# STM32L010RBT6 register map
File version: 1.0
Registers are 32-bit, access not given, reset 0x0 unless marked. A register's access mark holds for its fields unless they carry their own. Offsets are from the block's base; [hi:lo] are bit positions; {n}, {i} and the like mark numbered series; 'fields as' and 'values as' point back to an identical list.

## DMA1
Base 0x40020000
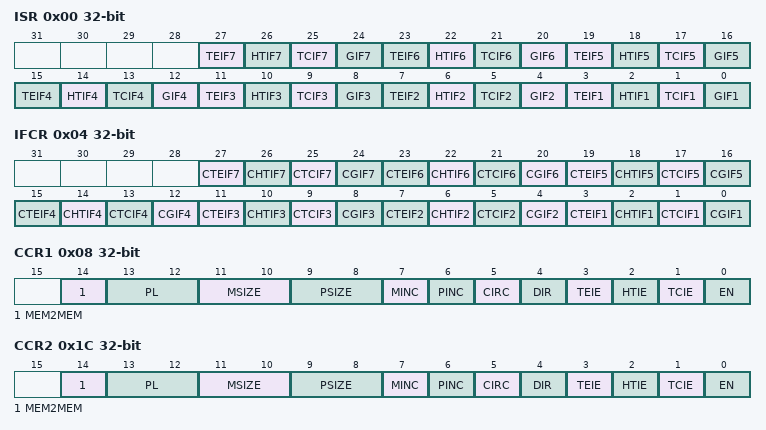
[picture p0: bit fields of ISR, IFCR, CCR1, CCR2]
0x00 ISR
  [4n-1] TEIF{n} (n=1..7), [4n-2] HTIF{n} (n=1..7), [4n-3] TCIF{n} (n=1..7), [4n-4] GIF{n} (n=1..7)
0x04 IFCR
  [4n-1] CTEIF{n} (n=1..7), [4n-2] CHTIF{n} (n=1..7), [4n-3] CTCIF{n} (n=1..7), [4n-4] CGIF{n} (n=1..7)
0x08 CCR1
  [14] MEM2MEM, [13:12] PL, [11:10] MSIZE, [9:8] PSIZE, [7] MINC, [6] PINC, [5] CIRC, [4] DIR, [3] TEIE, [2] HTIE, [1] TCIE, [0] EN
0x0C CNDTR1
  [15:0] NDT
0x10 CPAR1
  [31:0] PA
{0x0+0x14*i} CMAR{i} (i=1..7)
  [31:0] MA
0x1C CCR2
  fields as CCR1
0x20 CNDTR2
  [15:0] NDT
0x24 CPAR2
  [31:0] PA
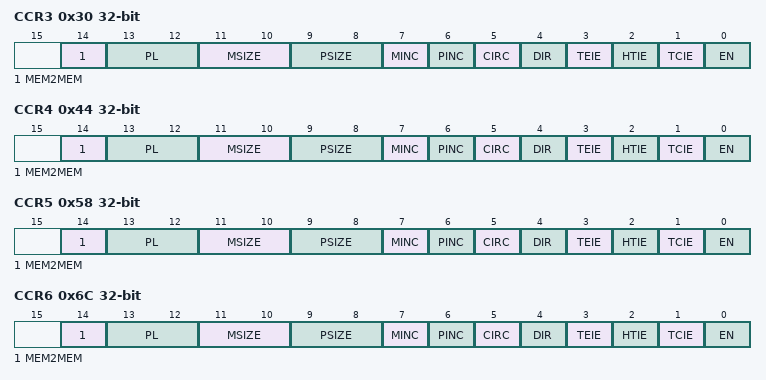
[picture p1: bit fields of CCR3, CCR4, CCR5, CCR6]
0x30 CCR3
  fields as CCR1
0x34 CNDTR3
  [15:0] NDT
0x38 CPAR3
  [31:0] PA
0x44 CCR4
  fields as CCR1
0x48 CNDTR4
  [15:0] NDT
0x4C CPAR4
  [31:0] PA
0x58 CCR5
  fields as CCR1
0x5C CNDTR5
  [15:0] NDT
0x60 CPAR5
  [31:0] PA
0x6C CCR6
  fields as CCR1
0x70 CNDTR6
  [15:0] NDT
0x74 CPAR6
  [31:0] PA
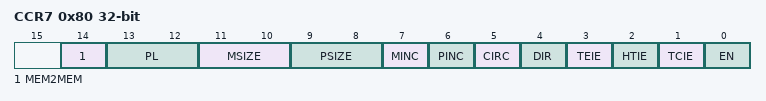
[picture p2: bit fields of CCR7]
0x80 CCR7
  fields as CCR1
0x84 CNDTR7
  [15:0] NDT
0x88 CPAR7
  [31:0] PA

## DMA1_CSELR
Base 0x400200A8
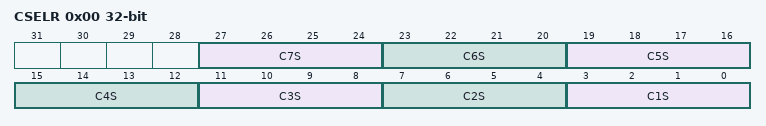
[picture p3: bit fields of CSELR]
0x00 CSELR
  [4n-1:4n-4] C{n}S (n=1..7)

## RCC
Base 0x40021000
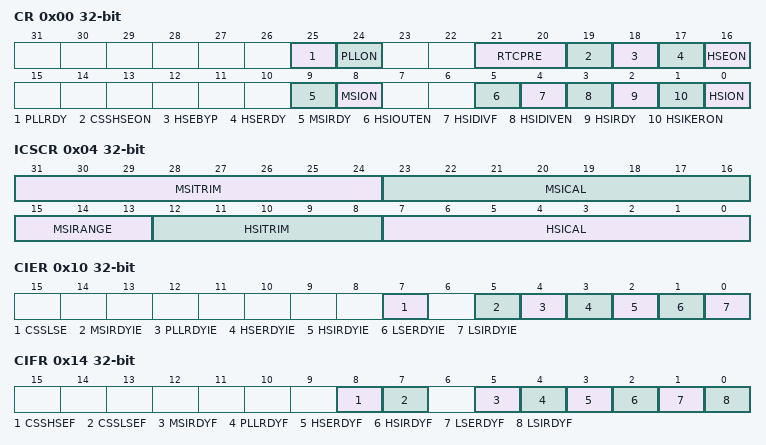
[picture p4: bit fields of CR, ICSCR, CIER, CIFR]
0x00 CR
  [25] PLLRDY, [24] PLLON, [21:20] RTCPRE, [19] CSSHSEON, [18] HSEBYP, [17] HSERDY, [16] HSEON, [9] MSIRDY, [8] MSION, [5] HSIOUTEN, [4] HSIDIVF, [3] HSIDIVEN, [2] HSIRDY, [1] HSIKERON, [0] HSION
0x04 ICSCR
  [31:24] MSITRIM, [23:16] MSICAL, [15:13] MSIRANGE, [12:8] HSITRIM, [7:0] HSICAL
0x08 CRRCR
0x0C CFGR
  [30:28] MCOPRE, [26] MCOSEL_HSE, [26:25] MCOSEL_LSI, [24] MCOSEL_SYSCLK, [23] PLLDIV3, [23:22] PLLDIV4, [21:18] PLLMUL, [16] PLLSRC, [15] STOPWUCK, [13:11] PPRE2, [10:8] PPRE1, [7:4] HPRE, [3:2] SWS, [1:0] SW
0x10 CIER
  [7] CSSLSE, [5] MSIRDYIE, [4] PLLRDYIE, [3] HSERDYIE, [2] HSIRDYIE, [1] LSERDYIE, [0] LSIRDYIE
0x14 CIFR
  [8] CSSHSEF, [7] CSSLSEF, [5] MSIRDYF, [4] PLLRDYF, [3] HSERDYF, [2] HSIRDYF, [1] LSERDYF, [0] LSIRDYF
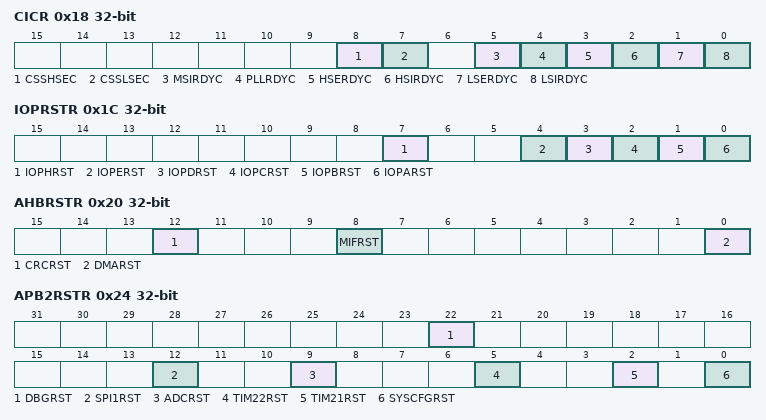
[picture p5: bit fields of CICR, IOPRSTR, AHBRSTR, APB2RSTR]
0x18 CICR
  [8] CSSHSEC, [7] CSSLSEC, [5] MSIRDYC, [4] PLLRDYC, [3] HSERDYC, [2] HSIRDYC, [1] LSERDYC, [0] LSIRDYC
0x1C IOPRSTR
  [7] IOPHRST, [4] IOPERST, [3] IOPDRST, [2] IOPCRST, [1] IOPBRST, [0] IOPARST
0x20 AHBRSTR
  [12] CRCRST, [8] MIFRST, [0] DMARST
0x24 APB2RSTR
  [22] DBGRST, [12] SPI1RST, [9] ADCRST, [5] TIM22RST, [2] TIM21RST, [0] SYSCFGRST
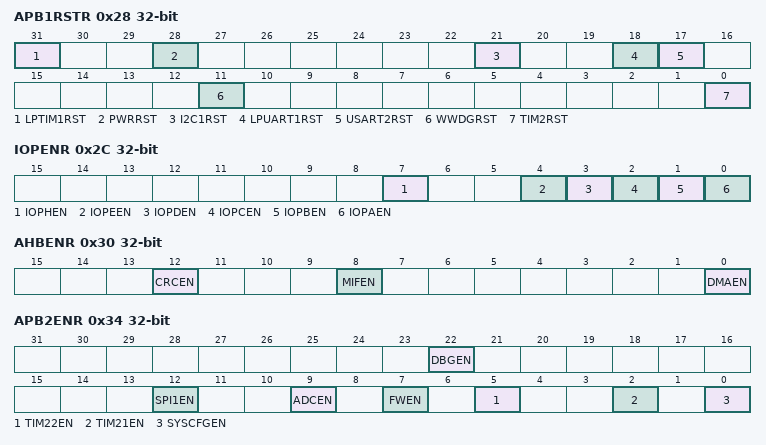
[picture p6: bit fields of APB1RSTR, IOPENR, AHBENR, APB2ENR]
0x28 APB1RSTR
  [31] LPTIM1RST, [28] PWRRST, [21] I2C1RST, [18] LPUART1RST, [17] USART2RST, [11] WWDGRST, [0] TIM2RST
0x2C IOPENR
  [7] IOPHEN, [4] IOPEEN, [3] IOPDEN, [2] IOPCEN, [1] IOPBEN, [0] IOPAEN
0x30 AHBENR
  [12] CRCEN, [8] MIFEN, [0] DMAEN
0x34 APB2ENR
  [22] DBGEN, [12] SPI1EN, [9] ADCEN, [7] FWEN, [5] TIM22EN, [2] TIM21EN, [0] SYSCFGEN
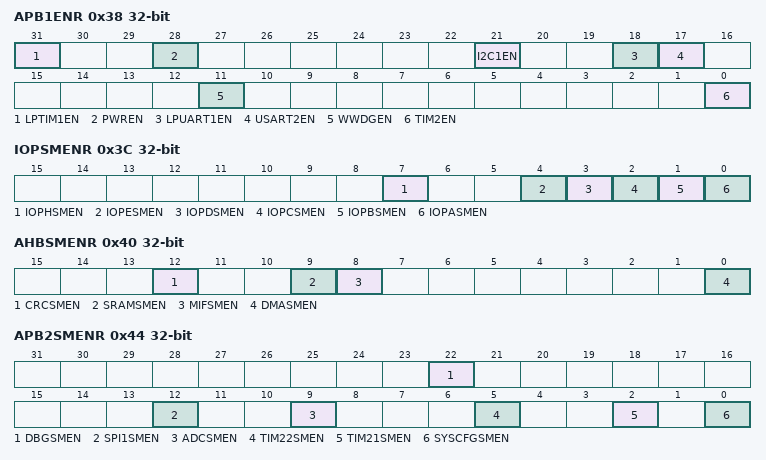
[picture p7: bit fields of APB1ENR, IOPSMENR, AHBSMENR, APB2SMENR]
0x38 APB1ENR
  [31] LPTIM1EN, [28] PWREN, [21] I2C1EN, [18] LPUART1EN, [17] USART2EN, [11] WWDGEN, [0] TIM2EN
0x3C IOPSMENR
  [7] IOPHSMEN, [4] IOPESMEN, [3] IOPDSMEN, [2] IOPCSMEN, [1] IOPBSMEN, [0] IOPASMEN
0x40 AHBSMENR
  [12] CRCSMEN, [9] SRAMSMEN, [8] MIFSMEN, [0] DMASMEN
0x44 APB2SMENR
  [22] DBGSMEN, [12] SPI1SMEN, [9] ADCSMEN, [5] TIM22SMEN, [2] TIM21SMEN, [0] SYSCFGSMEN
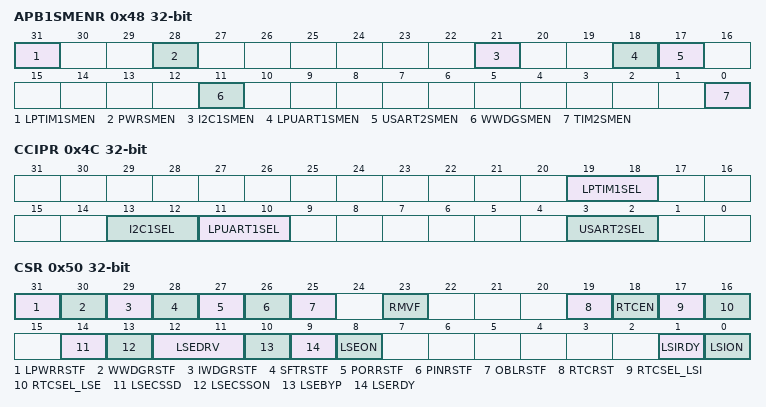
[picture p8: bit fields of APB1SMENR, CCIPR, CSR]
0x48 APB1SMENR
  [31] LPTIM1SMEN, [28] PWRSMEN, [21] I2C1SMEN, [18] LPUART1SMEN, [17] USART2SMEN, [11] WWDGSMEN, [0] TIM2SMEN
0x4C CCIPR
  [19:18] LPTIM1SEL, [13:12] I2C1SEL, [11:10] LPUART1SEL, [3:2] USART2SEL
0x50 CSR
  [31] LPWRRSTF, [30] WWDGRSTF, [29] IWDGRSTF, [28] SFTRSTF, [27] PORRSTF, [26] PINRSTF, [25] OBLRSTF, [23] RMVF, [19] RTCRST, [18] RTCEN, [17] RTCSEL_LSI, [16] RTCSEL_LSE, [14] LSECSSD, [13] LSECSSON, [12:11] LSEDRV, [10] LSEBYP, [9] LSERDY, [8] LSEON, [1] LSIRDY, [0] LSION

## FLASH
Base 0x40022000
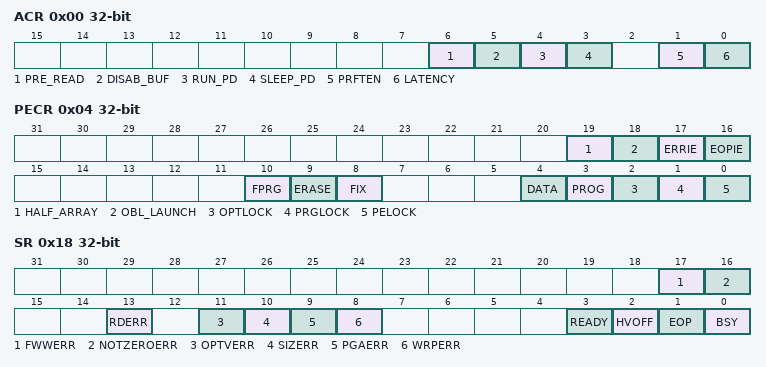
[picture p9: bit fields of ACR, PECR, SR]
0x00 ACR
  [6] PRE_READ, [5] DISAB_BUF, [4] RUN_PD, [3] SLEEP_PD, [1] PRFTEN, [0] LATENCY
0x04 PECR
  [19] HALF_ARRAY, [18] OBL_LAUNCH, [17] ERRIE, [16] EOPIE, [10] FPRG, [9] ERASE, [8] FIX, [4] DATA, [3] PROG, [2] OPTLOCK, [1] PRGLOCK, [0] PELOCK
0x08 PDKEYR
0x0C PEKEYR
0x10 PRGKEYR
0x14 OPTKEYR
0x18 SR
  [17] FWWERR, [16] NOTZEROERR, [13] RDERR, [11] OPTVERR, [10] SIZERR, [9] PGAERR, [8] WRPERR, [3] READY, [2] HVOFF, [1] EOP, [0] BSY
0x1C OPTR
  [31] BOOT1, [22] nRST_STDBY, [21] nRST_STOP, [22:20] USER, [19:16] BOR_LEV, [8] WPRMOD, [7:0] RDPROT
0x20 WRPR
  [15:0] WRP

## CRC
Base 0x40023000
0x00 DR
0x04 IDR 8-bit
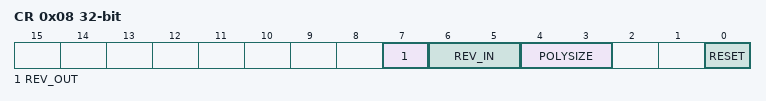
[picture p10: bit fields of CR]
0x08 CR
  [7] REV_OUT, [6:5] REV_IN, [4:3] POLYSIZE, [0] RESET
0x10 INIT
0x14 POL

## GPIOA
Base 0x50000000
Same registers: GPIOB 0x50000400, GPIOC 0x50000800, GPIOD 0x50000C00, GPIOE 0x50001000, GPIOH 0x50001C00
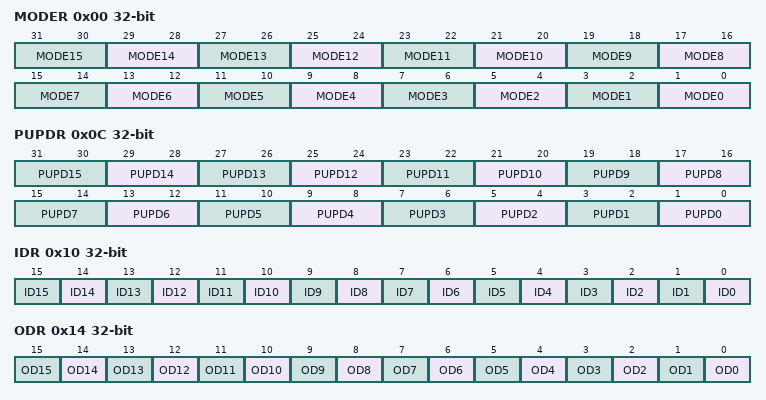
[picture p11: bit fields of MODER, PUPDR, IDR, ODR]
0x00 MODER
  [2n+1:2n] MODE{n} (n=0..15)
0x04 OTYPER
0x08 OSPEEDR
0x0C PUPDR
  [2n+1:2n] PUPD{n} (n=0..15)
0x10 IDR
  [n] ID{n} (n=0..15)
0x14 ODR
  [n] OD{n} (n=0..15)
0x18 BSRR
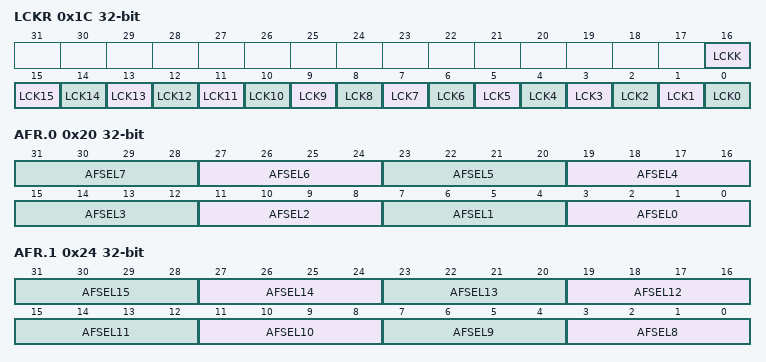
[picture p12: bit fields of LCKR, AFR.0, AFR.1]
0x1C LCKR
  [16] LCKK, [n] LCK{n} (n=0..15)
0x20 AFR.0
  [4n+3:4n] AFSEL{n} (n=0..7)
0x24 AFR.1
  [4n-29:4n-32] AFSEL{n} (n=8..15)
0x28 BRR
